# PIC32CZ2051CA70144 device description
Architecture: CORTEX-M7; Family: PIC32C; Series: PIC32CZCA70
Registers are 32-bit, read-write, no defined reset value unless marked. A register's access mark holds for its fields unless they carry their own. Offsets are from the block's base; [hi:lo] are bit positions; {n}, {i} and the like mark numbered series.

## MCAN_RXBE — Rx Buffer Element
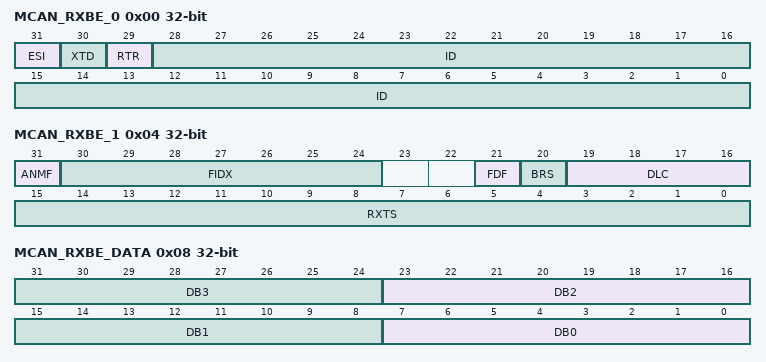
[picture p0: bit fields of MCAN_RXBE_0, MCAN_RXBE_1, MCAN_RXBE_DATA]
0x00 MCAN_RXBE_0 — Rx Buffer Element 0
  [31] ESI — Error State Indicator
  [30] XTD — Extended Identifier
  [29] RTR — Remote Transmission Request
  [28:0] ID — Identifier
0x04 MCAN_RXBE_1 — Rx Buffer Element 1
  [31] ANMF — Accepted Non-matching Frame
  [30:24] FIDX — Filter Index
  [21] FDF — FD Format
  [20] BRS — Bit Rate Switch
  [19:16] DLC — Data Length Code
  [15:0] RXTS — Rx Timestamp
0x08 MCAN_RXBE_DATA — Rx Buffer Element Data
  [8n+7:8n] DB{n} (n=0..3) — Data Byte {n}

## MCAN_RXF0E — Rx FIFO 0 Element
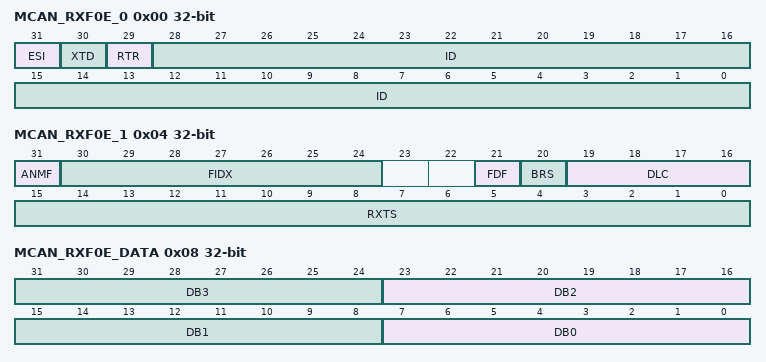
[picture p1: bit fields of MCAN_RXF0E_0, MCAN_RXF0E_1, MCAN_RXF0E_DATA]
0x00 MCAN_RXF0E_0 — Rx FIFO 0 Element 0
  [31] ESI — Error State Indicator
  [30] XTD — Extended Identifier
  [29] RTR — Remote Transmission Request
  [28:0] ID — Identifier
0x04 MCAN_RXF0E_1 — Rx FIFO 0 Element 1
  [31] ANMF — Accepted Non-matching Frame
  [30:24] FIDX — Filter Index
  [21] FDF — FD Format
  [20] BRS — Bit Rate Switch
  [19:16] DLC — Data Length Code
  [15:0] RXTS — Rx Timestamp
0x08 MCAN_RXF0E_DATA — Rx FIFO 0 Element Data
  [8n+7:8n] DB{n} (n=0..3) — Data Byte {n}

## MCAN_RXF1E — Rx FIFO 1 Element
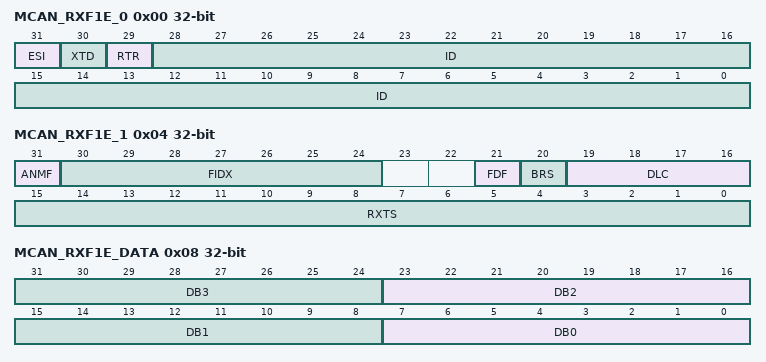
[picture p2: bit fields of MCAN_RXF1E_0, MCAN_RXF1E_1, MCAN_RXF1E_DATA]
0x00 MCAN_RXF1E_0 — Rx FIFO 1 Element 0
  [31] ESI — Error State Indicator
  [30] XTD — Extended Identifier
  [29] RTR — Remote Transmission Request
  [28:0] ID — Identifier
0x04 MCAN_RXF1E_1 — Rx FIFO 1 Element 1
  [31] ANMF — Accepted Non-matching Frame
  [30:24] FIDX — Filter Index
  [21] FDF — FD Format
  [20] BRS — Bit Rate Switch
  [19:16] DLC — Data Length Code
  [15:0] RXTS — Rx Timestamp
0x08 MCAN_RXF1E_DATA — Rx FIFO 1 Element Data
  [8n+7:8n] DB{n} (n=0..3) — Data Byte {n}

## MCAN_TXBE — Tx Buffer Element
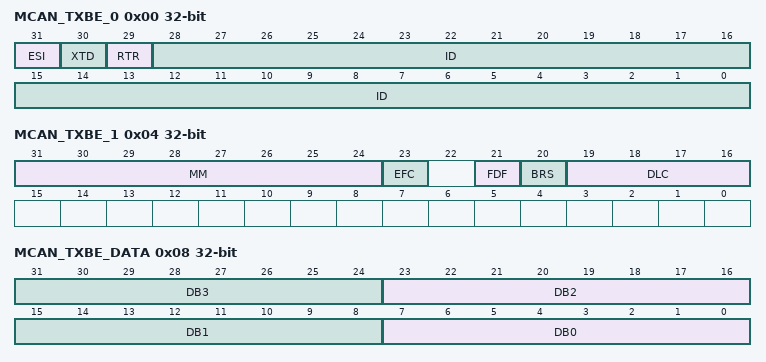
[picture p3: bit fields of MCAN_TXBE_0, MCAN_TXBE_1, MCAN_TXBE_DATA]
0x00 MCAN_TXBE_0 — Tx Buffer Element 0
  [31] ESI — Error State Indicator
  [30] XTD — Extended Identifier
  [29] RTR — Remote Transmission Request
  [28:0] ID — Identifier
0x04 MCAN_TXBE_1 — Tx Buffer Element 1
  [31:24] MM — Message Marker
  [23] EFC — Event FIFO Control
  [21] FDF — FD Format
  [20] BRS — Bit Rate Switch
  [19:16] DLC — Data Length Code
0x08 MCAN_TXBE_DATA — Tx Buffer Element Data
  [8n+7:8n] DB{n} (n=0..3) — Data Byte {n}

## MCAN_TXEFE — Tx Event FIFO Element
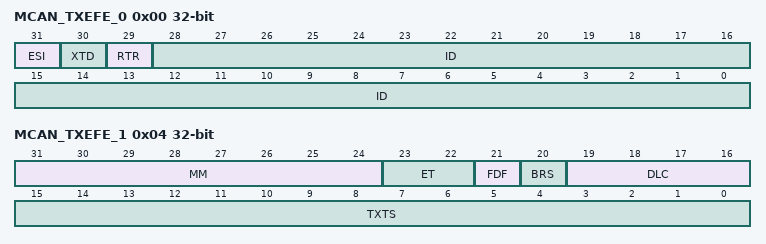
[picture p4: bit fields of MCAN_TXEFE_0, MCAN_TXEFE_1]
0x00 MCAN_TXEFE_0 — Tx Event FIFO Element 0
  [31] ESI — Error State Indicator
  [30] XTD — Extended Identifier
  [29] RTR — Remote Transmission Request
  [28:0] ID — Identifier
0x04 MCAN_TXEFE_1 — Tx Event FIFO Element 1
  [31:24] MM — Message Marker
  [23:22] ET — Event Type
    1=TXE (Tx event); 2=TXC (Transmission in spite of cancellation)
  [21] FDF — FD Format
  [20] BRS — Bit Rate Switch
  [19:16] DLC — Data Length Code
  [15:0] TXTS — Tx Timestamp

## MCAN_SIDFE — Standard Message ID Filter Element
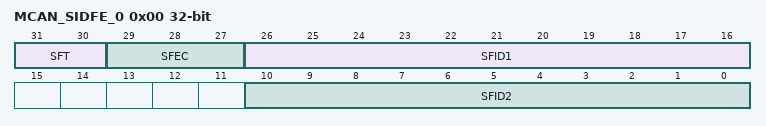
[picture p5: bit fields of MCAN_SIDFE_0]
0x00 MCAN_SIDFE_0 — Standard Message ID Filter Element 0
  [31:30] SFT — Standard Filter Type
    0=RANGE (Range filter from SFID1 to SFID2); 1=DUAL (Dual ID filter for SF1ID or SF2ID); 2=CLASSIC (Classic filter)
  [29:27] SFEC — Standard Filter Element Configuration
    0=DISABLE (Disable filter element); 1=STF0M (Store in Rx FIFO 0 if filter matches); 2=STF1M (Store in Rx FIFO 1 if filter matches); 3=REJECT (Reject ID if filter matches); 4=PRIORITY (Set priority if filter matches); 5=PRIF0M (Set priority and store in FIFO 0 if filter matches); 6=PRIF1M (Set priority and store in FIFO 1 if filter matches); 7=STRXBUF (Store into Rx Buffer)
  [26:16] SFID1 — Standard Filter ID 1
  [10:0] SFID2 — Standard Filter ID 2

## MCAN_XIDFE — Extended Message ID Filter Element
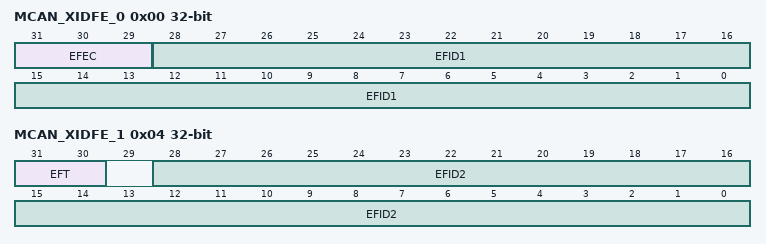
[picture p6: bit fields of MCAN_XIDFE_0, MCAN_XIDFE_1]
0x00 MCAN_XIDFE_0 — Extended Message ID Filter Element 0
  [31:29] EFEC — Extended Filter Element Configuration
    0=DISABLE (Disable filter element); 1=STF0M (Store in Rx FIFO 0 if filter matches); 2=STF1M (Store in Rx FIFO 1 if filter matches); 3=REJECT (Reject ID if filter matches); 4=PRIORITY (Set priority if filter matches); 5=PRIF0M (Set priority and store in FIFO 0 if filter matches); 6=PRIF1M (Set priority and store in FIFO 1 if filter matches); 7=STRXBUF (Store into Rx Buffer)
  [28:0] EFID1 — Extended Filter ID 1
0x04 MCAN_XIDFE_1 — Extended Message ID Filter Element 1
  [31:30] EFT — Extended Filter Type
    0=RANGE (Range filter from EFID1 to EFID2); 1=DUAL (Dual ID filter for EFID1 or EFID2); 2=CLASSIC (Classic filter); 3=RANGE_NO_XIDAM (Range filter from EFID1 to EFID2 with no XIDAM mask)
  [28:0] EFID2 — Extended Filter ID 2
